# STM32U3C5 register map
File version: 1.0
CPU: CM33 r0p1, little endian, MPU, FPU, 4 interrupt priority bits
Registers are 32-bit, read-write, reset 0x0 unless marked. A register's access mark holds for its fields unless they carry their own. Offsets are from the block's base; [hi:lo] are bit positions; {n}, {i} and the like mark numbered series.

## GTZC1_MPCBB1 — GTZC1_MPCBB1 address block description
Base 0x40032C00
Same registers: SEC_GTZC1_MPCBB1 0x50032C00
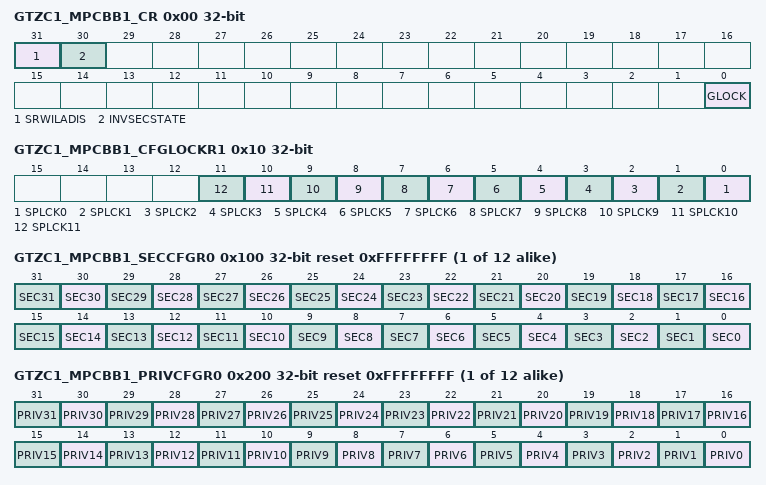
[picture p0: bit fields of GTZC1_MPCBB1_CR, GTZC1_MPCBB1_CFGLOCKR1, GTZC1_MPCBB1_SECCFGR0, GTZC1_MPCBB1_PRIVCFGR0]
0x00 GTZC1_MPCBB1_CR (alternate view of GTZC1_TZSC_CR) — GTZC1 SRAM1 MPCBB control register
  [31] SRWILADIS — Secure read/write illegal access disable
    0=Enabled, secure read/write access not allowed on nonsecure SRAM block; 1=Disabled, secure read/write access allowed on nonsecure SRAM block
  [30] INVSECSTATE — SRAM1 clock security state
    0=SRAM clocks are secure if a secure area exists in the MPCBB, and nonsecure if there is no secure area; 1=SRAM clocks are nonsecure even if a secure area exists in the MPCBB, and secure even if no secure block is set in the MPCBB
  [0] GLOCK — Lock the control register of the MPCBB until next reset
    0=Control register not locked; 1=Control register locked
0x10 GTZC1_MPCBB1_CFGLOCKR1 (alternate view of GTZC1_TZSC_SECCFGR1) — GTZC1 SRAM1 MPCBB configuration lock register 1
  [all] fields
    0=GTZC1_MPCBB1_SECCFGRi and GTZC1_MPCBB1_PRIVCFGRi can be written; 1=Writes to GTZC1_MPCBB1_SECCFGRi and GTZC1_MPCBB1_PRIVCFGRi are ignored
  [n] SPLCK{n} (n=0..11) — Security/privilege configuration lock for super-block i
{0x100+4i} GTZC1_MPCBB1_SECCFGR{i} reset 0xFFFFFFFF (i=0..11) — GTZC1 SRAM1 MPCBB security configuration for super-block {i} register
  [all] fields
    0=Nonsecure access only to block i, belonging to super-block x; 1=Secure access only to block i, belonging to super-block x
  [n] SEC{n} (n=0..31) — Security configuration for block i
{0x200+4i} GTZC1_MPCBB1_PRIVCFGR{i} reset 0xFFFFFFFF (i=0..11) — GTZC1 SRAM1 MPCBB privileged configuration for super-block {i} register
  [all] fields
    0=Privileged and unprivileged access to block i, belonging to super-block x; 1=Only privileged access to block i, belonging to super-block x
  [n] PRIV{n} (n=0..31) — Privileged configuration for block i, belonging to super-block x

## GTZC1_MPCBB2 — GTZC1_MPCBB2 address block description
Base 0x40033000
Same registers: SEC_GTZC1_MPCBB2 0x50033000
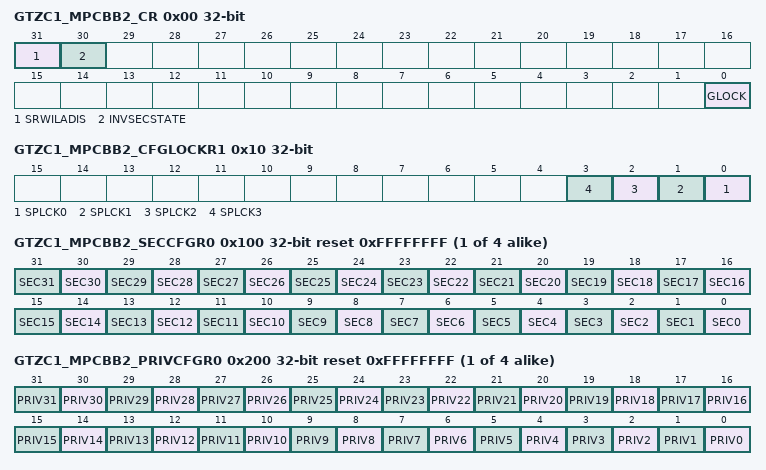
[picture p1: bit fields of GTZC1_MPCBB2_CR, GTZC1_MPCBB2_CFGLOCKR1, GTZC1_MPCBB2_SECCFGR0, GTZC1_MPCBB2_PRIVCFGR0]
0x00 GTZC1_MPCBB2_CR (alternate view of GTZC1_TZSC_CR) — GTZC1 SRAM2 MPCBB control register
  [31] SRWILADIS — Secure read/write illegal access disable
    0=Enabled, secure read/write access not allowed on nonsecure SRAM block; 1=Disabled, secure read/write access allowed on nonsecure SRAM block
  [30] INVSECSTATE — SRAM2 clock security state
    0=SRAM clocks are secure if a secure area exists in the MPCBB, and nonsecure if there is no secure area; 1=SRAM clocks are nonsecure even if a secure area exists in the MPCBB, and secure even if no secure block is set in the MPCBB
  [0] GLOCK — Lock the control register of the MPCBB until next reset
    0=Control register not locked; 1=Control register locked
0x10 GTZC1_MPCBB2_CFGLOCKR1 (alternate view of GTZC1_TZSC_SECCFGR1) — GTZC1 SRAM2 MPCBB configuration lock register 1
  [all] fields
    0=GTZC1_MPCBB2_SECCFGRi and GTZC1_MPCBB2_PRIVCFGRi can be written; 1=Writes to GTZC1_MPCBB2_SECCFGRi and GTZC1_MPCBB2_PRIVCFGRi are ignored
  [n] SPLCK{n} (n=0..3) — Security/privilege configuration lock for super-block i
{0x100+4i} GTZC1_MPCBB2_SECCFGR{i} reset 0xFFFFFFFF (alternate view of GTZC1_MPCBB1_SECCFGR{i}) (i=0..3) — GTZC1 SRAM2 MPCBB security configuration for super-block {i} register
  [all] fields
    0=Nonsecure access only to block i, belonging to super-block x; 1=Secure access only to block i, belonging to super-block x
  [n] SEC{n} (n=0..31) — Security configuration for block i
{0x200+4i} GTZC1_MPCBB2_PRIVCFGR{i} reset 0xFFFFFFFF (alternate view of GTZC1_MPCBB1_PRIVCFGR{i}) (i=0..3) — GTZC1 SRAM2 MPCBB privileged configuration for super-block {i} register
  [all] fields
    0=Privileged and unprivileged access to block i, belonging to super-block x; 1=Only privileged access to block i, belonging to super-block x
  [n] PRIV{n} (n=0..31) — Privileged configuration for block i, belonging to super-block x
